# TLE987x register map
Vendor: Infineon; File version: 3.8
CPU: CM3 r0p0, little endian, no MPU, no FPU, 4 interrupt priority bits
Registers are 32-bit, read-write, reset 0x0 unless marked. A register's access mark holds for its fields unless they carry their own. Offsets are from the block's base; [hi:lo] are bit positions; {n}, {i} and the like mark numbered series; 'fields as' and 'values as' point back to an identical list.

## LIN — Local Interconnect Network
Base 0x4801E000
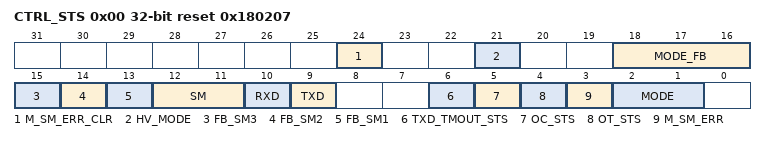
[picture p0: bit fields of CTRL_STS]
0x00 CTRL_STS access per field reset 0x180207 (reset mask 0xFFF81BFF) — LIN Transceiver Control and Status
  [24] M_SM_ERR_CLR rw — LIN Transceiver Mode or Slope Mode Error Clear
    0=no_action (Status unchanged); 1=Clear (Status clear)
  [21] HV_MODE rw — LIN Transceiver High Voltage Input - Output Mode
    0=DISABLE (High Voltage Mode Entry is disabled); 1=ENABLE (High Voltage Mode Entry is enabled)
  [18:16] MODE_FB ro — Feedback Signals for LIN Transmitter Mode Settings
  [15] FB_SM3 ro — Feedback Signal 3 for Slope Mode Setting
  [14] FB_SM2 ro — Feedback Signal 2 for Slope Mode Setting
  [13] FB_SM1 ro — Feedback Signal 1 for Slope Mode Setting
  [12:11] SM rw — LIN Transmitter Slope mode control
    0=Normal_Slope_Mode (for max. 20 kBaud); 1=Fast_Slope_Mode (for max. 40 kBaud); 2=Low_Slope_Mode (for max. 10.4 kBaud); 3=Flash_Mode (for max. 150 kBaud)
  [10] RXD ro — Output Signal of Receiver
  [9] TXD rw — LIN Transmitter switch on (only used when LIN_HV_MODE is set)
    0=Pull_Down_LIN_Line (Transmitter is switched on); 1=Pull_Up_Resistor_is_active (Transmitter is switched off)
  [6] TXD_TMOUT_STS ro — LIN TXD time-out status
    0=NO_TIMEOUT (no time-out occured); 1=TIMEOUT (time-out occured)
  [5] OC_STS ro — LIN Receiver Overcurrent Status
    0=no_Overcurrent (overcurrent status occured); 1=overcurrent status occured
  [4] OT_STS ro — LIN Receiver Overtemperature Status
    0=no_Overtemperature (overtemperature occured); 1=overtemperature occured
  [3] M_SM_ERR ro — LIN Transceiver Mode or Slope Mode Error
    0=no_Mode_or_Slope_Mode_Error (Status (see corresponding Feedback registers)); 1=Mode_or_Slope_Mode_Error (Status (see corresponding Feedback registers))
  [2:1] MODE rw — LIN transceiver power mode control
    0=LIN_Sleep_Mode (LIN module switched to LIN Sleep Mode); 1=LIN_Receive_Only_Mode (LIN module switched to LIN Receive Only Mode); 3=LIN_Normal_Mode (LIN module switched to LIN Normal Mode)

## PORT — GPIO PORTs
Base 0x48028000
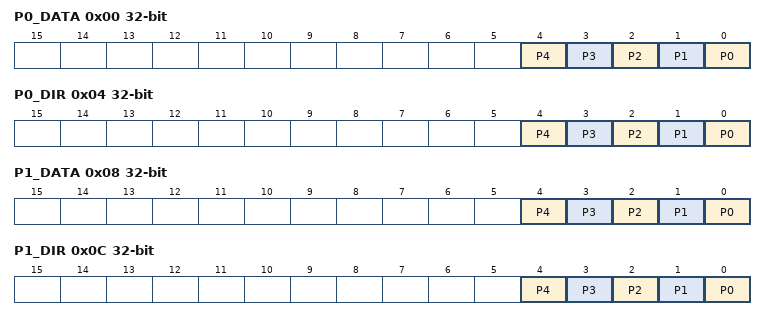
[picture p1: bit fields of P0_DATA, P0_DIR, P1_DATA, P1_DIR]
0x00 P0_DATA reset not defined — Port 0 Data Register
  [all] fields
    0=Port 0 pin n data value = 0; 1=Port 0 pin n data value = 1
  [n] P{n} (n=0..4) — Port 0 Pin {n} Data Value
0x04 P0_DIR — Port 0 Direction Register
  [all] fields
    0=Direction is set to input (default); 1=Direction is set to output
  [n] P{n} (n=0..4) — Port 0 Pin {n} Direction Control
0x08 P1_DATA reset not defined — Port 1 Data Register
  [all] fields
    0=Port 1 pin n data value = 0; 1=Port 1 pin n data value = 1
  [n] P{n} (n=0..4) — Port 1 Pin {n} Data Value
0x0C P1_DIR — Port 1 Direction Register
  [all] fields
    values as the fields of P0_DIR
  [n] P{n} (n=0..4) — Port 1 Pin {n} Direction Control
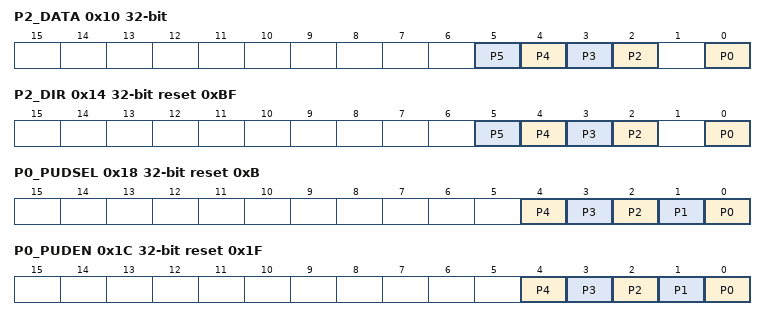
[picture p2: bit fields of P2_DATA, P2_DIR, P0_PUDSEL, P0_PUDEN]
0x10 P2_DATA ro reset not defined — Port 2 Data Register
  [all] fields
    0=Port 2 pin n data value = 0; 1=Port 2 pin n data value = 1
  [n] P{n} (n=2..5) — Port 2 Pin {n} Data Value
  [0] P0 — Port 2 Pin 0 Data Value
0x14 P2_DIR reset 0xBF — Port 2 Direction Register
  [all] fields
    0=Input driver is enabled; 1=Input driver is disabled (default)
  [n] P{n} (n=2..5) — Port 2 Pin {n} Driver Control
  [0] P0 — Port 2 Pin 0 Driver Control
0x18 P0_PUDSEL reset 0xB — Port 0 Pull-Up/Pull-Down Select Register
  [all] fields
    0=Pull-down device is selected; 1=Pull-up device is selected
  [n] P{n} (n=0..4) — Pull-Up/Pull-Down Select Port 0 Bit {n}
0x1C P0_PUDEN reset 0x1F — Port 0 Pull-Up/Pull-Down Enable Register
  [all] fields
    0=Pull-up or Pull-down device is disabled; 1=Pull-up or Pull-down device is enabled
  [n] P{n} (n=0..4) — Pull-Up/Pull-Down Enable at Port 0 Bit {n}
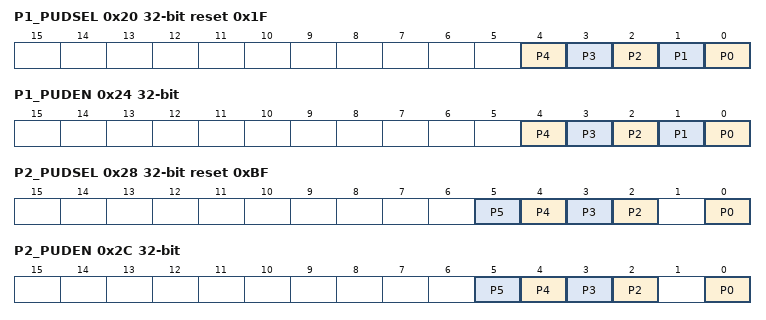
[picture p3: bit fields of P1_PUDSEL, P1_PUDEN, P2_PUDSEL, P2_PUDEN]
0x20 P1_PUDSEL reset 0x1F — Port 1 Pull-Up/Pull-Down Select Register
  [all] fields
    0=Pull-down device is selected; 1=Pull-up device is selected (default)
  [n] P{n} (n=0..4) — Pull-Up/Pull-Down Select Port 1 Bit {n}
0x24 P1_PUDEN — Port 1 Pull-Up/Pull-Down Enable Register
  [all] fields
    0=Pull-up or Pull-down device is disabled (default); 1=Pull-up or Pull-down device is enabled
  [n] P{n} (n=0..4) — Pull-Up/Pull-Down Enable at Port 1 Bit {n}
0x28 P2_PUDSEL reset 0xBF — Port 2 Pull-Up/Pull-Down Select Register
  [all] fields
    values as the fields of P1_PUDSEL
  [n] P{n} (n=2..5) — Pull-Up/Pull-Down Select Port 2 Bit {n}
  [0] P0 — Pull-Up/Pull-Down Select Port 2 Bit 0
0x2C P2_PUDEN — Port 2 Pull-Up/Pull-Down Enable Register
  [all] fields
    values as the fields of P1_PUDEN
  [n] P{n} (n=2..5) — Pull-Up/Pull-Down Enable at Port 2 Bit {n}
  [0] P0 — Pull-Up/Pull-Down Enable at Port 2 Bit 0
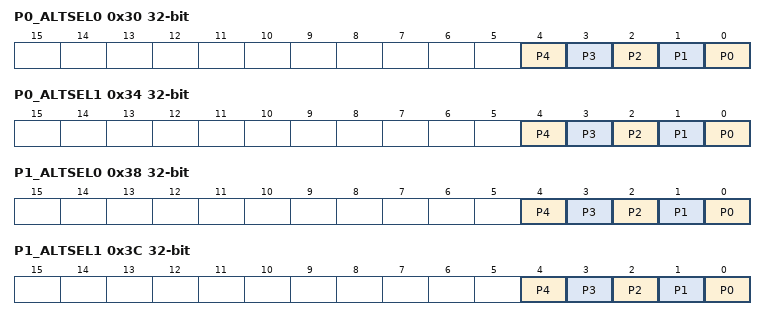
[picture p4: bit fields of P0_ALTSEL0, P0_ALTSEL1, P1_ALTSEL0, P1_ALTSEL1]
0x30 P0_ALTSEL0 — Port 0 Alternate Select Register
  [n] P{n} (n=0..4) — Alternate Select Port 0 Bit {n}
0x34 P0_ALTSEL1 — Port 0 Alternate Select Register
  [n] P{n} (n=0..4) — Alternate Select Port 0 Bit {n}
0x38 P1_ALTSEL0 — Port 1 Alternate Select Register
  [n] P{n} (n=0..4) — Alternate Select Port 1 Bit {n}
0x3C P1_ALTSEL1 — Port 1 Alternate Select Register
  [n] P{n} (n=0..4) — Alternate Select Port 1 Bit {n}
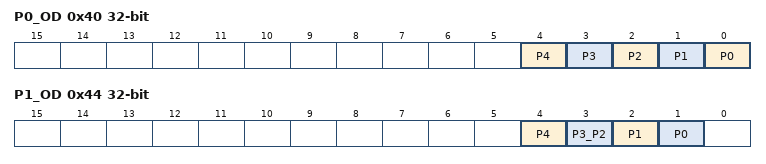
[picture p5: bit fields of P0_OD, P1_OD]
0x40 P0_OD — Port 0 Open Drain Control Register
  [all] fields
    0=Normal Mode, output is actively driven for 0 and 1 state (default); 1=Open Drain Mode, output is actively driven only for 0 state
  [n] P{n} (n=0..4) — Port 0 Pin {n} Open Drain Mode
0x44 P1_OD — Port 1 Open Drain Control Register
  [all] fields
    values as the fields of P0_OD
  [4] P4 — P1.4 Open Drain Mode
  [3] P3_P2 — P1.3/P1.2 Open Drain Mode
  [2] P1 — P1.1 Open Drain Mode
  [1] P0 — P1.0 Open Drain Mode
